VERSION ""

NS_ :

BU_: EBCM EON CAM RADAR PCM EPS VSA SCM BDY XXX EPB

BO_ 513 SOMETHING: 8 XXX
 SG_ NEW_SIGNAL_1 : 3|6@0- (1,0) [-63|63] "" XXX

BO_ 576 CUR_LANE_LEFT_1: 8 XXX
 SG_ FULL : 63|64@0+ (1,0) [0|9223372036854775807] "" XXX
 SG_ PARM_1 : 6|11@0- (1,0) [-1023|1023] "" XXX
 SG_ PARM_2 : 22|11@0- (1,0) [-1023|1023] "" XXX
 SG_ PARM_3 : 39|9@0+ (1,0) [0|511] "" XXX
 SG_ PARM_4 : 46|7@0+ (1,0) [0|127] "" XXX
 SG_ PARM_5 : 54|7@0+ (1,0) [0|127] "" XXX
 SG_ FRAME_ID : 11|4@0+ (1,0) [0|15] "" XXX

BO_ 577 CUR_LANE_LEFT_2: 8 XXX
 SG_ FULL : 63|64@0+ (1,0) [0|9223372036854775807] "" XXX
 SG_ PARM_6 : 3|8@0+ (1,0) [0|255] "" XXX
 SG_ PARM_7 : 22|11@0- (1,0) [-1023|1023] "" XXX
 SG_ PARM_8 : 24|4@0+ (1,0) [0|15] "" XXX
 SG_ PARM_11 : 27|4@0+ (1,0) [0|15] "" XXX
 SG_ PARM_12 : 12|4@0+ (1,0) [0|15] "" XXX
 SG_ PARM_13 : 40|4@0+ (1,0) [0|15] "" XXX
 SG_ PARM_9 : 38|11@0- (1,0) [-1023|1023] "" XXX
 SG_ PARM_10 : 54|7@0- (1,0) [-63|63] "" XXX
 SG_ DASHED_LINE : 14|1@0+ (1,0) [0|1] "" XXX
 SG_ SOLID_LINE : 13|1@0+ (1,0) [0|1] "" XXX
 SG_ FRAME_ID : 7|4@0+ (1,0) [0|15] "" XXX

BO_ 579 CUR_LANE_RIGHT_1: 8 XXX
 SG_ FULL : 63|64@0+ (1,0) [0|9223372036854775807] "" XXX
 SG_ PARM_1 : 6|11@0- (1,0) [-1023|1023] "" XXX
 SG_ PARM_2 : 22|11@0- (1,0) [-1023|1023] "" XXX
 SG_ PARM_3 : 39|9@0+ (1,0) [0|511] "" XXX
 SG_ PARM_4 : 46|7@0+ (1,0) [0|127] "" XXX
 SG_ PARM_5 : 54|7@0+ (1,0) [0|127] "" XXX
 SG_ FRAME_ID : 11|4@0+ (1,0) [0|15] "" XXX

BO_ 580 CUR_LANE_RIGHT_2: 8 XXX
 SG_ FULL : 63|64@0+ (1,0) [0|9223372036854775807] "" XXX
 SG_ PARM_6 : 3|8@0+ (1,0) [0|255] "" XXX
 SG_ PARM_7 : 22|11@0- (1,0) [-1023|1023] "" XXX
 SG_ PARM_8 : 24|4@0+ (1,0) [0|15] "" XXX
 SG_ PARM_11 : 27|4@0+ (1,0) [0|15] "" XXX
 SG_ PARM_12 : 12|4@0+ (1,0) [0|15] "" XXX
 SG_ PARM_13 : 40|4@0+ (1,0) [0|15] "" XXX
 SG_ PARM_9 : 38|11@0- (1,0) [-1023|1023] "" XXX
 SG_ PARM_10 : 54|7@0- (1,0) [-63|63] "" XXX
 SG_ DASHED_LINE : 14|1@0+ (1,0) [0|1] "" XXX
 SG_ SOLID_LINE : 13|1@0+ (1,0) [0|1] "" XXX
 SG_ FRAME_ID : 7|4@0+ (1,0) [0|15] "" XXX

BO_ 582 ADJ_LANE_LEFT_1: 8 XXX
 SG_ FULL : 63|64@0+ (1,0) [0|9223372036854775807] "" XXX
 SG_ PARM_1 : 6|11@0- (1,0) [-1023|1023] "" XXX
 SG_ PARM_2 : 22|11@0- (1,0) [-1023|1023] "" XXX
 SG_ PARM_3 : 39|9@0+ (1,0) [0|511] "" XXX
 SG_ PARM_4 : 46|7@0+ (1,0) [0|127] "" XXX
 SG_ PARM_5 : 54|7@0+ (1,0) [0|127] "" XXX
 SG_ FRAME_ID : 11|4@0+ (1,0) [0|15] "" XXX

BO_ 583 ADJ_LANE_LEFT_2: 8 XXX
 SG_ FULL : 63|64@0+ (1,0) [0|9223372036854775807] "" XXX
 SG_ PARM_6 : 3|8@0+ (1,0) [0|255] "" XXX
 SG_ PARM_7 : 22|11@0- (1,0) [-1023|1023] "" XXX
 SG_ PARM_8 : 24|4@0+ (1,0) [0|15] "" XXX
 SG_ PARM_11 : 27|4@0+ (1,0) [0|15] "" XXX
 SG_ PARM_12 : 12|4@0+ (1,0) [0|15] "" XXX
 SG_ PARM_13 : 40|4@0+ (1,0) [0|15] "" XXX
 SG_ PARM_9 : 38|11@0- (1,0) [-1023|1023] "" XXX
 SG_ PARM_10 : 54|7@0- (1,0) [-63|63] "" XXX
 SG_ DASHED_LINE : 14|1@0+ (1,0) [0|1] "" XXX
 SG_ SOLID_LINE : 13|1@0+ (1,0) [0|1] "" XXX
 SG_ FRAME_ID : 7|4@0+ (1,0) [0|15] "" XXX

BO_ 585 ADJ_LANE_RIGHT_1: 8 XXX
 SG_ FULL : 63|64@0+ (1,0) [0|9223372036854775807] "" XXX
 SG_ PARM_1 : 6|11@0- (1,0) [-1023|1023] "" XXX
 SG_ PARM_2 : 22|11@0- (1,0) [-1023|1023] "" XXX
 SG_ PARM_3 : 39|9@0+ (1,0) [0|511] "" XXX
 SG_ PARM_4 : 46|7@0+ (1,0) [0|127] "" XXX
 SG_ PARM_5 : 54|7@0+ (1,0) [0|127] "" XXX
 SG_ FRAME_ID : 11|4@0+ (1,0) [0|15] "" XXX

BO_ 586 ADJ_LANE_RIGHT_2: 8 XXX
 SG_ FULL : 63|64@0+ (1,0) [0|9223372036854775807] "" XXX
 SG_ PARM_6 : 3|8@0+ (1,0) [0|255] "" XXX
 SG_ PARM_7 : 22|11@0- (1,0) [-1023|1023] "" XXX
 SG_ PARM_8 : 24|4@0+ (1,0) [0|15] "" XXX
 SG_ PARM_11 : 27|4@0+ (1,0) [0|15] "" XXX
 SG_ PARM_12 : 12|4@0+ (1,0) [0|15] "" XXX
 SG_ PARM_13 : 40|4@0+ (1,0) [0|15] "" XXX
 SG_ PARM_9 : 38|11@0- (1,0) [-1023|1023] "" XXX
 SG_ PARM_10 : 54|7@0- (1,0) [-63|63] "" XXX
 SG_ DASHED_LINE : 14|1@0+ (1,0) [0|1] "" XXX
 SG_ SOLID_LINE : 13|1@0+ (1,0) [0|1] "" XXX
 SG_ FRAME_ID : 7|4@0+ (1,0) [0|15] "" XXX

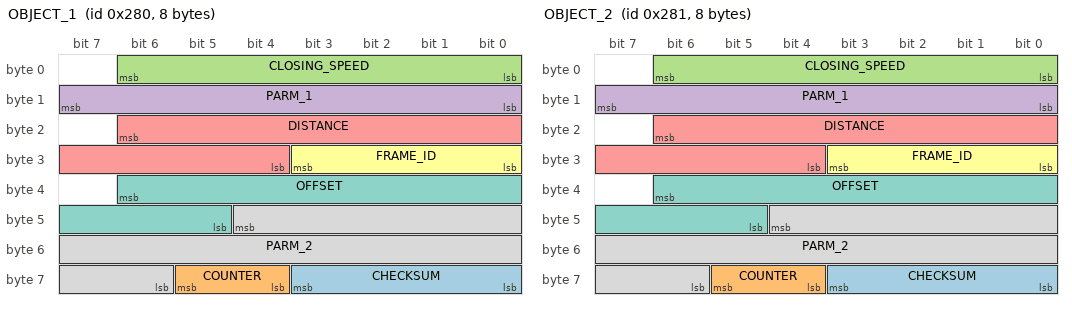
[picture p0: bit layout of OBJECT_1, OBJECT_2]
BO_ 640 OBJECT_1: 8 XXX
 SG_ CHECKSUM : 56|4@1+ (1,0) [0|15] "" XXX
 SG_ COUNTER : 60|2@1+ (1,0) [0|15] "" XXX
 SG_ CLOSING_SPEED : 6|7@0- (1,0) [-127|127] "" XXX
 SG_ PARM_1 : 15|8@0+ (1,0) [0|1] "" XXX
 SG_ DISTANCE : 22|11@0+ (1,0) [0|8191] "" XXX
 SG_ FRAME_ID : 27|4@0+ (1,0) [0|1] "" XXX
 SG_ OFFSET : 38|10@0- (1,0) [-1023|1023] "" XXX
 SG_ PARM_2 : 44|15@0+ (1,0) [0|31] "" XXX

BO_ 641 OBJECT_2: 8 XXX
 SG_ CHECKSUM : 56|4@1+ (1,0) [0|15] "" XXX
 SG_ COUNTER : 60|2@1+ (1,0) [0|15] "" XXX
 SG_ CLOSING_SPEED : 6|7@0- (1,0) [-127|127] "" XXX
 SG_ PARM_1 : 15|8@0+ (1,0) [0|1] "" XXX
 SG_ DISTANCE : 22|11@0+ (1,0) [0|8191] "" XXX
 SG_ FRAME_ID : 27|4@0+ (1,0) [0|1] "" XXX
 SG_ OFFSET : 38|10@0- (1,0) [-1023|1023] "" XXX
 SG_ PARM_2 : 44|15@0+ (1,0) [0|31] "" XXX

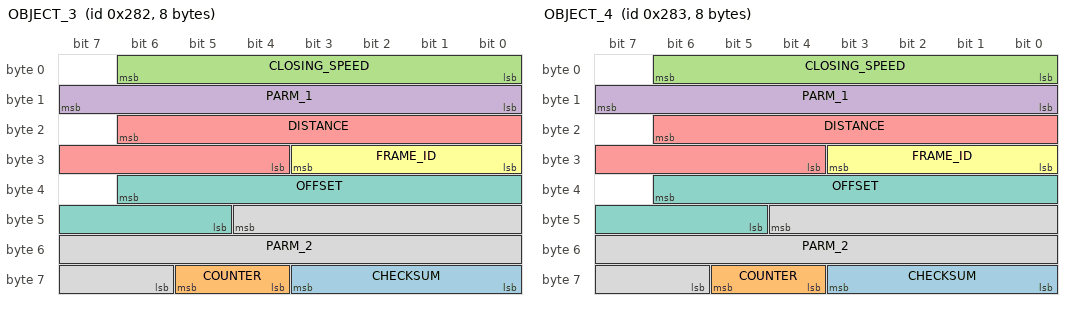
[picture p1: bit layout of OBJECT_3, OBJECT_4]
BO_ 642 OBJECT_3: 8 XXX
 SG_ CHECKSUM : 56|4@1+ (1,0) [0|15] "" XXX
 SG_ COUNTER : 60|2@1+ (1,0) [0|15] "" XXX
 SG_ CLOSING_SPEED : 6|7@0- (1,0) [-127|127] "" XXX
 SG_ PARM_1 : 15|8@0+ (1,0) [0|1] "" XXX
 SG_ DISTANCE : 22|11@0+ (1,0) [0|8191] "" XXX
 SG_ FRAME_ID : 27|4@0+ (1,0) [0|1] "" XXX
 SG_ OFFSET : 38|10@0- (1,0) [-1023|1023] "" XXX
 SG_ PARM_2 : 44|15@0+ (1,0) [0|31] "" XXX

BO_ 643 OBJECT_4: 8 XXX
 SG_ CHECKSUM : 56|4@1+ (1,0) [0|15] "" XXX
 SG_ COUNTER : 60|2@1+ (1,0) [0|15] "" XXX
 SG_ CLOSING_SPEED : 6|7@0- (1,0) [-127|127] "" XXX
 SG_ PARM_1 : 15|8@0+ (1,0) [0|1] "" XXX
 SG_ DISTANCE : 22|11@0+ (1,0) [0|8191] "" XXX
 SG_ FRAME_ID : 27|4@0+ (1,0) [0|1] "" XXX
 SG_ OFFSET : 38|10@0- (1,0) [-1023|1023] "" XXX
 SG_ PARM_2 : 44|15@0+ (1,0) [0|31] "" XXX

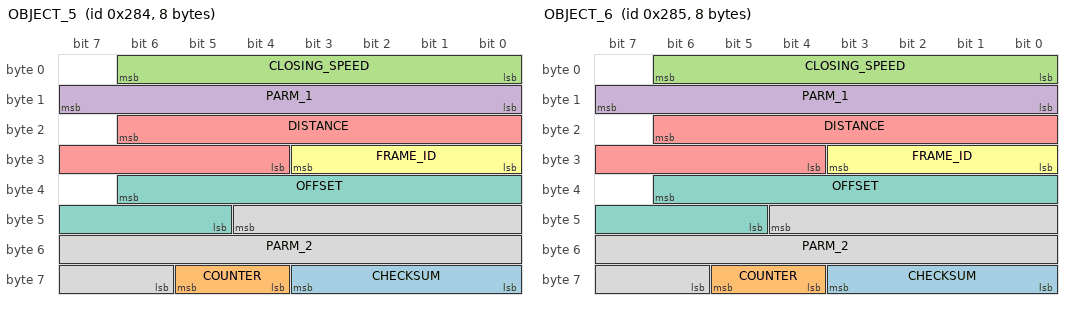
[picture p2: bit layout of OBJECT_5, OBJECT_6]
BO_ 644 OBJECT_5: 8 XXX
 SG_ CHECKSUM : 56|4@1+ (1,0) [0|15] "" XXX
 SG_ COUNTER : 60|2@1+ (1,0) [0|15] "" XXX
 SG_ CLOSING_SPEED : 6|7@0- (1,0) [-127|127] "" XXX
 SG_ PARM_1 : 15|8@0+ (1,0) [0|1] "" XXX
 SG_ DISTANCE : 22|11@0+ (1,0) [0|8191] "" XXX
 SG_ FRAME_ID : 27|4@0+ (1,0) [0|1] "" XXX
 SG_ OFFSET : 38|10@0- (1,0) [-1023|1023] "" XXX
 SG_ PARM_2 : 44|15@0+ (1,0) [0|31] "" XXX

BO_ 645 OBJECT_6: 8 XXX
 SG_ CHECKSUM : 56|4@1+ (1,0) [0|15] "" XXX
 SG_ COUNTER : 60|2@1+ (1,0) [0|15] "" XXX
 SG_ CLOSING_SPEED : 6|7@0- (1,0) [-127|127] "" XXX
 SG_ PARM_1 : 15|8@0+ (1,0) [0|1] "" XXX
 SG_ DISTANCE : 22|11@0+ (1,0) [0|8191] "" XXX
 SG_ FRAME_ID : 27|4@0+ (1,0) [0|1] "" XXX
 SG_ OFFSET : 38|10@0- (1,0) [-1023|1023] "" XXX
 SG_ PARM_2 : 44|15@0+ (1,0) [0|31] "" XXX
